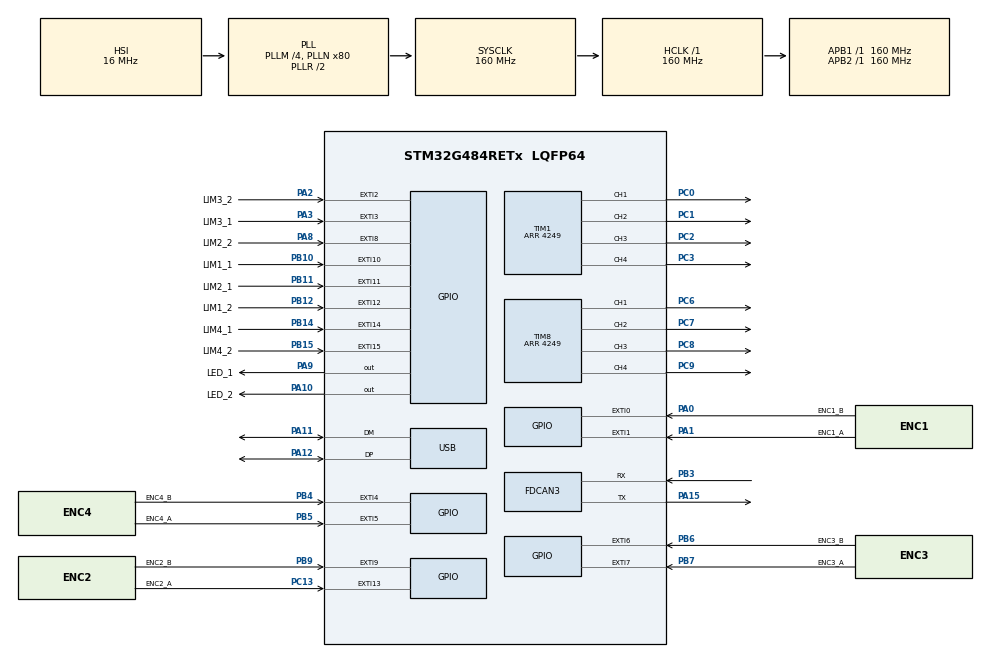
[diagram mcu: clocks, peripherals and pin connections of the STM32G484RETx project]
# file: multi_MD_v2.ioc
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FDCAN3.CalculateBaudRateNominal=1000000
FDCAN3.CalculateTimeBitNominal=1000
FDCAN3.CalculateTimeQuantumNominal=50.0
FDCAN3.ExtFiltersNbr=0
FDCAN3.NominalPrescaler=4
FDCAN3.NominalTimeSeg1=16
FDCAN3.NominalTimeSeg2=3
Mcu.Family=STM32G4
Mcu.Name=STM32G484RETx
Mcu.Package=LQFP64
NVIC.EXTI0_IRQn=true\:0\:0\:false\:false\:true\:true\:true\:true
NVIC.EXTI15_10_IRQn=true\:0\:0\:false\:false\:true\:true\:true\:true
NVIC.EXTI1_IRQn=true\:0\:0\:false\:false\:true\:true\:true\:true
NVIC.EXTI2_IRQn=true\:0\:0\:false\:false\:true\:true\:true\:true
NVIC.EXTI3_IRQn=true\:0\:0\:false\:false\:true\:true\:true\:true
NVIC.EXTI4_IRQn=true\:0\:0\:false\:false\:true\:true\:true\:true
NVIC.EXTI9_5_IRQn=true\:0\:0\:false\:false\:true\:true\:true\:true
NVIC.FDCAN3_IT0_IRQn=true\:0\:0\:false\:false\:true\:true\:true\:true
NVIC.PriorityGroup=NVIC_PRIORITYGROUP_4
PA0.GPIO_Label=ENC1_B
PA0.GPIO_ModeDefaultEXTI=GPIO_MODE_IT_RISING_FALLING
PA0.Signal=GPXTI0
PA1.GPIO_Label=ENC1_A
PA1.GPIO_ModeDefaultEXTI=GPIO_MODE_IT_RISING_FALLING
PA1.Signal=GPXTI1
PA10.GPIO_Label=LED_2
PA10.GPIO_ModeDefaultOutputPP=GPIO_MODE_OUTPUT_PP
PA10.GPIO_PuPd=GPIO_NOPULL
PA10.GPIO_Speed=GPIO_SPEED_FREQ_VERY_HIGH
PA10.PinState=GPIO_PIN_RESET
PA10.Signal=GPIO_Output
PA11.Mode=Device
PA11.Signal=USB_DM
PA12.Mode=Device
PA12.Signal=USB_DP
PA13.Mode=Serial_Wire
PA13.Signal=SYS_JTMS-SWDIO
PA14.Mode=Serial_Wire
PA14.Signal=SYS_JTCK-SWCLK
PA15.GPIO_Speed=GPIO_SPEED_FREQ_VERY_HIGH
PA15.Mode=FDCAN_Activate
PA15.Signal=FDCAN3_TX
PA2.GPIO_Label=LIM3_2
PA2.GPIO_ModeDefaultEXTI=GPIO_MODE_IT_FALLING
PA2.Signal=GPXTI2
PA3.GPIO_Label=LIM3_1
PA3.GPIO_ModeDefaultEXTI=GPIO_MODE_IT_FALLING
PA3.Signal=GPXTI3
PA8.GPIO_Label=LIM2_2
PA8.GPIO_ModeDefaultEXTI=GPIO_MODE_IT_FALLING
PA8.Signal=GPXTI8
PA9.GPIO_Label=LED_1
PA9.GPIO_ModeDefaultOutputPP=GPIO_MODE_OUTPUT_PP
PA9.GPIO_PuPd=GPIO_NOPULL
PA9.GPIO_Speed=GPIO_SPEED_FREQ_VERY_HIGH
PA9.PinState=GPIO_PIN_RESET
PA9.Signal=GPIO_Output
PB10.GPIO_Label=LIM1_1
PB10.GPIO_ModeDefaultEXTI=GPIO_MODE_IT_FALLING
PB10.Signal=GPXTI10
PB11.GPIO_Label=LIM2_1
PB11.GPIO_ModeDefaultEXTI=GPIO_MODE_IT_FALLING
PB11.Signal=GPXTI11
PB12.GPIO_Label=LIM1_2
PB12.GPIO_ModeDefaultEXTI=GPIO_MODE_IT_FALLING
PB12.Signal=GPXTI12
PB14.GPIO_Label=LIM4_1
PB14.GPIO_ModeDefaultEXTI=GPIO_MODE_IT_FALLING
PB14.Signal=GPXTI14
PB15.GPIO_Label=LIM4_2
PB15.GPIO_ModeDefaultEXTI=GPIO_MODE_IT_FALLING
PB15.Signal=GPXTI15
PB3.GPIO_Speed=GPIO_SPEED_FREQ_VERY_HIGH
PB3.Mode=FDCAN_Activate
PB3.Signal=FDCAN3_RX
PB4.GPIO_Label=ENC4_B
PB4.GPIO_ModeDefaultEXTI=GPIO_MODE_IT_RISING_FALLING
PB4.Signal=GPXTI4
PB5.GPIO_Label=ENC4_A
PB5.GPIO_ModeDefaultEXTI=GPIO_MODE_IT_RISING_FALLING
PB5.Signal=GPXTI5
PB6.GPIO_Label=ENC3_B
PB6.GPIO_ModeDefaultEXTI=GPIO_MODE_IT_RISING_FALLING
PB6.Signal=GPXTI6
PB7.GPIO_Label=ENC3_A
PB7.GPIO_ModeDefaultEXTI=GPIO_MODE_IT_RISING_FALLING
PB7.Signal=GPXTI7
PB9.GPIO_Label=ENC2_B
PB9.GPIO_ModeDefaultEXTI=GPIO_MODE_IT_RISING_FALLING
PB9.Signal=GPXTI9
PC0.GPIO_PuPd=GPIO_PULLDOWN
PC0.GPIO_Speed=GPIO_SPEED_FREQ_VERY_HIGH
PC0.Signal=S_TIM1_CH1
PC1.GPIO_PuPd=GPIO_PULLDOWN
PC1.GPIO_Speed=GPIO_SPEED_FREQ_VERY_HIGH
PC1.Signal=S_TIM1_CH2
PC13.GPIO_Label=ENC2_A
PC13.GPIO_ModeDefaultEXTI=GPIO_MODE_IT_RISING_FALLING
PC13.Signal=GPXTI13
PC2.GPIO_PuPd=GPIO_PULLDOWN
PC2.GPIO_Speed=GPIO_SPEED_FREQ_VERY_HIGH
PC2.Signal=S_TIM1_CH3
PC3.GPIO_PuPd=GPIO_PULLDOWN
PC3.GPIO_Speed=GPIO_SPEED_FREQ_VERY_HIGH
PC3.Signal=S_TIM1_CH4
PC6.GPIO_PuPd=GPIO_PULLDOWN
PC6.GPIO_Speed=GPIO_SPEED_FREQ_VERY_HIGH
PC6.Signal=S_TIM8_CH1
PC7.GPIO_PuPd=GPIO_PULLDOWN
PC7.GPIO_Speed=GPIO_SPEED_FREQ_VERY_HIGH
PC7.Signal=S_TIM8_CH2
PC8.GPIO_PuPd=GPIO_PULLDOWN
PC8.GPIO_Speed=GPIO_SPEED_FREQ_VERY_HIGH
PC8.Signal=S_TIM8_CH3
PC9.GPIO_PuPd=GPIO_PULLDOWN
PC9.GPIO_Speed=GPIO_SPEED_FREQ_VERY_HIGH
PC9.Signal=S_TIM8_CH4
ProjectManager.HeapSize=0x200
ProjectManager.StackSize=0x400
ProjectManager.TargetToolchain=CMake
RCC.ADC12Freq_Value=160000000
RCC.ADC345Freq_Value=160000000
RCC.AHBFreq_Value=160000000
RCC.APB1Freq_Value=160000000
RCC.APB1TimFreq_Value=160000000
RCC.APB2Freq_Value=160000000
RCC.APB2TimFreq_Value=160000000
RCC.CK48CLockSelection=RCC_USBCLKSOURCE_HSI48
RCC.CortexFreq_Value=160000000
RCC.EXTERNAL_CLOCK_VALUE=12288000
RCC.FDCANCLockSelection=RCC_FDCANCLKSOURCE_PLL
RCC.HCLKFreq_Value=160000000
RCC.HSE_VALUE=8000000
RCC.HSI48_VALUE=48000000
RCC.HSI_VALUE=16000000
RCC.LSE_VALUE=32768
RCC.PLLM=RCC_PLLM_DIV4
RCC.PLLN=80
RCC.PLLQ=RCC_PLLQ_DIV4
RCC.SYSCLKFreq_VALUE=160000000
RCC.SYSCLKSource=RCC_SYSCLKSOURCE_PLLCLK
RCC.USBFreq_Value=48000000
RCC.VCOOutputFreq_Value=320000000
SH.S_TIM1_CH1.0=TIM1_CH1,PWM Generation1 CH1
SH.S_TIM1_CH2.0=TIM1_CH2,PWM Generation2 CH2
SH.S_TIM1_CH3.0=TIM1_CH3,PWM Generation3 CH3
SH.S_TIM1_CH4.0=TIM1_CH4,PWM Generation4 CH4
SH.S_TIM8_CH1.0=TIM8_CH1,PWM Generation1 CH1
SH.S_TIM8_CH2.0=TIM8_CH2,PWM Generation2 CH2
SH.S_TIM8_CH3.0=TIM8_CH3,PWM Generation3 CH3
SH.S_TIM8_CH4.0=TIM8_CH4,PWM Generation4 CH4
TIM1.Channel-PWM\ Generation1\ CH1=TIM_CHANNEL_1
TIM1.Channel-PWM\ Generation2\ CH2=TIM_CHANNEL_2
TIM1.Channel-PWM\ Generation3\ CH3=TIM_CHANNEL_3
TIM1.Channel-PWM\ Generation4\ CH4=TIM_CHANNEL_4
TIM1.PeriodNoDither=4249
TIM8.Channel-PWM\ Generation1\ CH1=TIM_CHANNEL_1
TIM8.Channel-PWM\ Generation2\ CH2=TIM_CHANNEL_2
TIM8.Channel-PWM\ Generation3\ CH3=TIM_CHANNEL_3
TIM8.Channel-PWM\ Generation4\ CH4=TIM_CHANNEL_4
TIM8.PeriodNoDither=4249
VP_SYS_VS_DBSignals.Mode=DisableDeadBatterySignals
board=custom

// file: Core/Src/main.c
/* USER CODE BEGIN Header */
/**
 ******************************************************************************
 * @file           : main.c
 * @brief          : Main program body
 ******************************************************************************
 * @attention
 *
 * Copyright (c) 2026 STMicroelectronics.
 * All rights reserved.
 *
 * This software is licensed under terms that can be found in the LICENSE file
 * in the root directory of this software component.
 * If no LICENSE file comes with this software, it is provided AS-IS.
 *
 ******************************************************************************
 */
/* USER CODE END Header */
#include "main.h"

#include "fdcan.h"
#include "gpio.h"
#include "tim.h"
#include "usb.h"

/* USER CODE BEGIN Includes */
#include "app/app.hpp"
/* USER CODE END Includes */

void SystemClock_Config(void);

int main(void)
{

    /* MCU Configuration--------------------------------------------------------*/

    /* Reset of all peripherals, Initializes the Flash interface and the Systick. */
    HAL_Init();

    /* Configure the system clock */
    SystemClock_Config();

    /* Initialize all configured peripherals */
    MX_GPIO_Init();
    MX_FDCAN3_Init();
    MX_TIM1_Init();
    MX_TIM8_Init();
    MX_USB_PCD_Init();
    /* USER CODE BEGIN 2 */
    setup();
    /* USER CODE END 2 */

    /* Infinite loop */
    while (1) {
        loop();

    }
}

void SystemClock_Config(void)
{
    RCC_OscInitTypeDef RCC_OscInitStruct = {0};
    RCC_ClkInitTypeDef RCC_ClkInitStruct = {0};

    /** Configure the main internal regulator output voltage
     */
    HAL_PWREx_ControlVoltageScaling(PWR_REGULATOR_VOLTAGE_SCALE1_BOOST);

    /** Initializes the RCC Oscillators according to the specified parameters
     * in the RCC_OscInitTypeDef structure.
     */
    RCC_OscInitStruct.OscillatorType      = RCC_OSCILLATORTYPE_HSI | RCC_OSCILLATORTYPE_HSI48;
    RCC_OscInitStruct.HSIState            = RCC_HSI_ON;
    RCC_OscInitStruct.HSICalibrationValue = RCC_HSICALIBRATION_DEFAULT;
    RCC_OscInitStruct.HSI48State          = RCC_HSI48_ON;
    RCC_OscInitStruct.PLL.PLLState        = RCC_PLL_ON;
    RCC_OscInitStruct.PLL.PLLSource       = RCC_PLLSOURCE_HSI;
    RCC_OscInitStruct.PLL.PLLM            = RCC_PLLM_DIV4;
    RCC_OscInitStruct.PLL.PLLN            = 80;
    RCC_OscInitStruct.PLL.PLLP            = RCC_PLLP_DIV2;
    RCC_OscInitStruct.PLL.PLLQ            = RCC_PLLQ_DIV4;
    RCC_OscInitStruct.PLL.PLLR            = RCC_PLLR_DIV2;
    if (HAL_RCC_OscConfig(&RCC_OscInitStruct) != HAL_OK) {
        Error_Handler();
    }

    /** Initializes the CPU, AHB and APB buses clocks
     */
    RCC_ClkInitStruct.ClockType =
        RCC_CLOCKTYPE_HCLK | RCC_CLOCKTYPE_SYSCLK | RCC_CLOCKTYPE_PCLK1 | RCC_CLOCKTYPE_PCLK2;
    RCC_ClkInitStruct.SYSCLKSource   = RCC_SYSCLKSOURCE_PLLCLK;
    RCC_ClkInitStruct.AHBCLKDivider  = RCC_SYSCLK_DIV1;
    RCC_ClkInitStruct.APB1CLKDivider = RCC_HCLK_DIV1;
    RCC_ClkInitStruct.APB2CLKDivider = RCC_HCLK_DIV1;

    if (HAL_RCC_ClockConfig(&RCC_ClkInitStruct, FLASH_LATENCY_4) != HAL_OK) {
        Error_Handler();
    }
}

void Error_Handler(void)
{
    __disable_irq();
    while (1) {
    }
}
